# S1C31W74 register map
Vendor: Epson; Series: S1C31W74; File version: 1.11
CPU: CM0PLUS r0p1, little endian, MPU, no FPU, VTOR, 2 interrupt priority bits
Registers are 16-bit, read-write, reset 0x0 unless marked. A register's access mark holds for its fields unless they carry their own. Offsets are from the block's base; [hi:lo] are bit positions; 'fields as' and 'values as' point back to an identical list.

## UART2_0 — UART2 channel 0 control
Base 0x40000380
Same registers: UART2_1 0x40000600
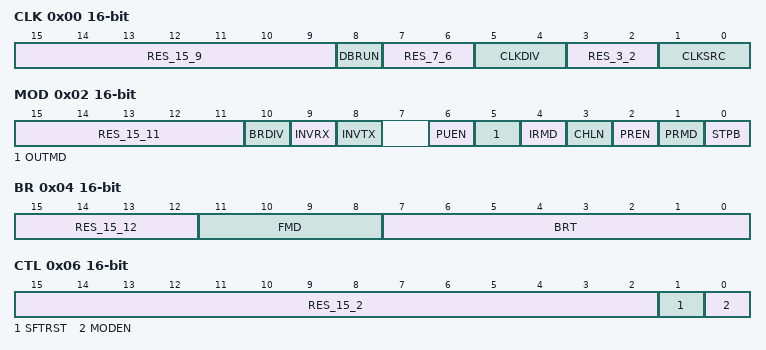
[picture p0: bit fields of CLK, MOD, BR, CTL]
0x00 CLK — Clock Control Register
  [15:9] RES_15_9 ro — Reserved bits
  [8] DBRUN — Enable clock on debug mode
    0=DISABLE; 1=ENABLE
  [7:6] RES_7_6 ro — Reserved bits
  [5:4] CLKDIV — Clock division select
  [3:2] RES_3_2 ro — Reserved bits
  [1:0] CLKSRC — Clock source select (can be write protected)
    0=IOSC; 1=OSC1; 2=OSC3; 3=EXOSC
0x02 MOD — Mode Register
  [15:11] RES_15_11 ro — Reserved bits
  [10] BRDIV — Baud Rate Division ratio
    0=DIV_1_16 (Ratio 1 over 16); 1=DIV_1_4 (Ration 1 over 4)
  [9] INVRX — Invert receive signal
    0=DISABLE (Disable input inverting function); 1=ENABLE (Enable input inverting function)
  [8] INVTX — Invert transmit signal
    0=DISABLE (Disable output inverting function); 1=ENABLE (Enable output inverting function)
  [6] PUEN — USIN pullup enable
    0=DISABLE (Disable pull-up); 1=ENABLE (Enable pull-up)
  [5] OUTMD — Output mode select
    0=PUSH_PULL (Push-pull output); 1=OPEN_DRAIN (Open-drain output)
  [4] IRMD — IrDA mode select
    0=DISABLE (Disable IrDA interface function); 1=ENABLE (Enable IrDA interface function)
  [3] CHLN — Character length
    0=7_BIT (7 bits); 1=8_BIT (8 bits)
  [2] PREN — Parity enable
    0=DISABLE (Disable parity function); 1=ENABLE (Enable parity function)
  [1] PRMD — Parity mode select
    0=EVEN (Even parity); 1=ODD (Odd parity)
  [0] STPB — Stop bit select
    0=1_BIT; 1=2_BIT (2 bits)
0x04 BR — Baud Rate Register
  [15:12] RES_15_12 ro — Reserved bits
  [11:8] FMD — Fine mode control
  [7:0] BRT — Baud rate setting
0x06 CTL — Control Register
  [15:2] RES_15_2 ro — Reserved bits
  [1] SFTRST write-1-sets — Soft reset
    on write: 0=NON (No effect); 1=RESET (Issue software reset) | on read: 0=STOPPED (Software reset has finished (During normal operation)); 1=RUNNING (Software reset is executing)
  [0] MODEN — UART2 enable
    0=DISABLE (Disable UART2 operations (The operating clock is stopped)); 1=ENABLE (Enable UART2 operations (The operating clock is supplied))
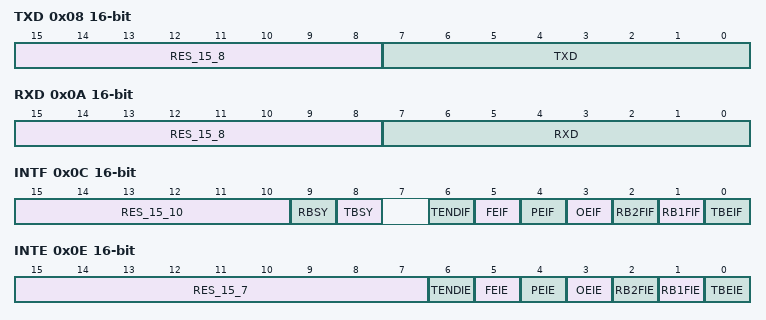
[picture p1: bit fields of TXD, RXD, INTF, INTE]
0x08 TXD — Transmit Data Register
  [15:8] RES_15_8 ro — Reserved bits
  [7:0] TXD — Transmit data
0x0A RXD ro — Receive Data Register
  [15:8] RES_15_8 — Reserved bits
  [7:0] RXD — Receive data
0x0C INTF — Status and Interrupt Flag Register
  [15:10] RES_15_10 ro — Reserved bits
  [9] RBSY ro — Receive busy status
    0=IDLE; 1=BUSY (During receiving)
  [8] TBSY ro — Transmit busy status
    0=IDLE; 1=BUSY (During sending)
  [6] TENDIF ro write-1-clears — End of transmission interrupt flag
    0=NOT_OCCURED (No cause of interrupt occurred); 1=OCCURED (Cause of interrupt occurred)
  [5] FEIF ro write-1-clears — Framing error interrupt flag
    values as TENDIF
  [4] PEIF ro write-1-clears — Parity error interrupt flag
    values as TENDIF
  [3] OEIF ro write-1-clears — Overrun error interrupt flag
    values as TENDIF
  [2] RB2FIF ro — Receive buffer 2byte full interrupt flag
    values as TENDIF
  [1] RB1FIF ro — Receive buffer 1byte full interrupt flag
    values as TENDIF
  [0] TBEIF ro — Transmit buffer empty interrupt flag
    values as TENDIF
0x0E INTE — Interrupt Enable Register
  [15:7] RES_15_7 ro — Reserved bits
  [6] TENDIE — End of transmission interrupt enable
    0=DISABLE; 1=ENABLE
  [5] FEIE — Framing error interrupt enable
    0=DISABLE; 1=ENABLE
  [4] PEIE — Parity error interrupt enable
    0=DISABLE; 1=ENABLE
  [3] OEIE — Overrun error interrupt enable
    0=DISABLE; 1=ENABLE
  [2] RB2FIE — Receive buffer 2byte full interrupt enable
    0=DISABLE; 1=ENABLE
  [1] RB1FIE — Receive buffer 1byte full interrupt enable
    0=DISABLE; 1=ENABLE
  [0] TBEIE — Transmit buffer empty interrupt enable
    0=DISABLE; 1=ENABLE
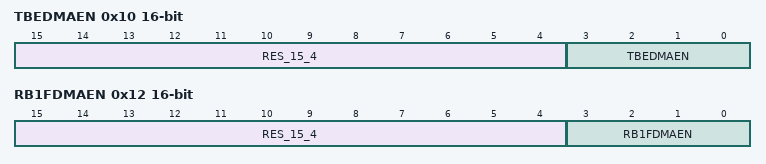
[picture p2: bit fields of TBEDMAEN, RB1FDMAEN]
0x10 TBEDMAEN — TBE DMA Enable Register
  [15:4] RES_15_4 ro — Reserved bits
  [3:0] TBEDMAEN — TBE DMA request enable
0x12 RB1FDMAEN — RB1F DMA Enable Register
  [15:4] RES_15_4 ro — Reserved bits
  [3:0] RB1FDMAEN — RB1F DMA ch3 request enable
